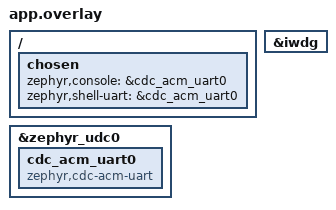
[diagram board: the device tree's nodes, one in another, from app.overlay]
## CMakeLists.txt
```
cmake_minimum_required(VERSION 3.20.0)

find_package(Zephyr REQUIRED HINTS $ENV{ZEPHYR_BASE})
project(my_zephyr_app)

target_sources(app PRIVATE src/main_latency.c)
```

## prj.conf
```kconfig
CONFIG_LOG=y
CONFIG_ZBUS_LOG_LEVEL_INF=y

CONFIG_THREAD_NAME=y

CONFIG_USB_DEVICE_STACK=y
CONFIG_USB_DEVICE_INITIALIZE_AT_BOOT=y
CONFIG_SERIAL=y
CONFIG_CONSOLE=y

CONFIG_UART_CONSOLE=y
CONFIG_UART_LINE_CTRL=y
CONFIG_ZBUS=y
CONFIG_WATCHDOG=y
CONFIG_TASK_WDT=y
CONFIG_TASK_WDT_CHANNELS=3
CONFIG_LOG_RATELIMIT=y
CONFIG_LOG_RATELIMIT_INTERVAL_MS=1000

CONFIG_SHELL=y
CONFIG_KERNEL_SHELL=y

CONFIG_THREAD_MONITOR=y
CONFIG_THREAD_NAME=y
CONFIG_INIT_STACKS=y
CONFIG_THREAD_STACK_INFO=y
# Enable DTR check so shell waits for terminal to connect
CONFIG_SHELL_BACKEND_SERIAL_CHECK_DTR=y
CONFIG_TRACING=y
CONFIG_TRACING_CTF=y
CONFIG_TRACING_ASYNC=y
CONFIG_TRACING_BACKEND_RAM=y
CONFIG_RAM_TRACING_BUFFER_SIZE=65536
CONFIG_TRACING_ISR=n
CONFIG_TRACING_SYSCALL=n

CONFIG_USE_SEGGER_RTT=y
CONFIG_SHELL_BACKEND_RTT=y
CONFIG_SEGGER_RTT_BUFFER_SIZE_UP=4096
CONFIG_SEGGER_RTT_BUFFER_SIZE_DOWN=64
```

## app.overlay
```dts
/{
	chosen {
	zephyr,console = &cdc_acm_uart0;
        zephyr,shell-uart =&cdc_acm_uart0;
	};
};

&zephyr_udc0{
	status="okay";
	cdc_acm_uart0: cdc_acm_uart0{
	compatible ="zephyr,cdc-acm-uart";
	};
};
&iwdg {
    status = "okay";
};
```

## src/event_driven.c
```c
/*
 * Zephyr Course: Intermediate - L4-TASK1: zbus listener and subscriber
 *
 * Architecture:
 * - Channel: sensor_chan carrying struct sensor_msg
 * - Publisher: sensor_thread publishes simulated sensor samples every 100 ms
 * - Listener: display_lis performs immediate display update in the publisher's context
 * - Subscriber: logger_sub thread uses zbus_sub_wait + zbus_chan_read for slower logging
 * - Observers: Both display_lis and logger_sub are registered via ZBUS_OBSERVERS on sensor_chan
 */

#include <zephyr/kernel.h>
#include <zephyr/logging/log.h>
#include <zephyr/zbus/zbus.h>

LOG_MODULE_REGISTER(l4_task1, LOG_LEVEL_INF);

#define STACK_SIZE         2048
#define SENSOR_PERIOD_MS    100
#define SENSOR_SAMPLE_COUNT  20
#define PUBLISHER_PRIORITY    5
#define SUBSCRIBER_PRIORITY   6

/* Sensor message structure */
struct sensor_msg {
    uint32_t timestamp_ms;
    int32_t temperature_mc;
    uint8_t seq;
};

/* Forward declaration for listener callback */
static void display_listener_cb(const struct zbus_channel *chan);

/* Fast display listener: executes synchronously in publisher's context */
ZBUS_LISTENER_DEFINE(display_lis, display_listener_cb);

/* Slower logging subscriber: uses message queue to unblock subscriber thread */
ZBUS_SUBSCRIBER_DEFINE(logger_sub, 8);

/*
 * ZBUS Channel Definition:
 * Carries struct sensor_msg with both display_lis and logger_sub observers
 */
ZBUS_CHAN_DEFINE(sensor_chan,
                 struct sensor_msg,
                 NULL,
                 NULL,
                 ZBUS_OBSERVERS(display_lis, logger_sub),
                 ZBUS_MSG_INIT(.timestamp_ms = 0,
                               .temperature_mc = 0,
                               .seq = 0));

/* Listener callback: runs in publisher thread context for fast notification */
static void display_listener_cb(const struct zbus_channel *chan)
{
    const struct sensor_msg *msg = zbus_chan_const_msg(chan);

    LOG_INF("[DISPLAY-LIS] (in %s context) seq=%u temp=%d mC",
            k_thread_name_get(k_current_get()),
            msg->seq,
            msg->temperature_mc);
}

/* Publisher thread: publishes sensor readings every 100 ms */
static void publisher_thread_fn(void *p1, void *p2, void *p3)
{
    ARG_UNUSED(p1); ARG_UNUSED(p2); ARG_UNUSED(p3);

    k_thread_name_set(k_current_get(), "publisher");

    LOG_INF("[PUBLISHER] Thread started, publishing %d samples every %d ms",
            SENSOR_SAMPLE_COUNT, SENSOR_PERIOD_MS);

    for (uint8_t i = 0; i < SENSOR_SAMPLE_COUNT; i++) {
        struct sensor_msg sample = {
            .timestamp_ms = k_uptime_get_32(),
            .temperature_mc = 22000 + (i * 450), /* Simulated temp: 22.0°C to 30.55°C */
            .seq = i,
        };

        LOG_INF("[PUBLISHER] Publishing sample seq=%u temp=%d mC",
                sample.seq, sample.temperature_mc);

        int ret = zbus_chan_pub(&sensor_chan, &sample, K_MSEC(100));
        if (ret != 0) {
            LOG_WRN("[PUBLISHER] zbus_chan_pub failed: %d", ret);
        }

        k_msleep(SENSOR_PERIOD_MS);
    }

    LOG_INF("[PUBLISHER] All samples published, publisher done");
}

/* Subscriber thread: performs slower decoupled logging */
static void subscriber_thread_fn(void *p1, void *p2, void *p3)
{
    ARG_UNUSED(p1); ARG_UNUSED(p2); ARG_UNUSED(p3);

    k_thread_name_set(k_current_get(), "logger");

    LOG_INF("[LOGGER-SUB] Thread started, waiting for channel events");

    const struct zbus_channel *chan = NULL;

    while (true) {
        /* Wait for notification on logger_sub */
        int ret = zbus_sub_wait(&logger_sub, &chan, K_MSEC(2000));
        if (ret != 0) {
            LOG_INF("[LOGGER-SUB] Timeout waiting for samples, subscriber completed");
            break;
        }

        /* Read the message from the channel */
        struct sensor_msg msg;
        ret = zbus_chan_read(chan, &msg, K_MSEC(100));
        if (ret != 0) {
            LOG_WRN("[LOGGER-SUB] zbus_chan_read failed: %d", ret);
            continue;
        }

        uint32_t latency_ms = k_uptime_get_32() - msg.timestamp_ms;
        LOG_INF("[LOGGER-SUB] (in %s context) seq=%u temp=%d mC latency=%u ms",
                k_thread_name_get(k_current_get()),
                msg.seq,
                msg.temperature_mc,
                latency_ms);

        /* Simulate slower logging I/O (e.g. disk or serial flash write) */
        k_msleep(180);
    }

    LOG_INF("[LOGGER-SUB] Logging thread exited cleanly");
}

/* Thread definitions */
K_THREAD_DEFINE(pub_tid, STACK_SIZE, publisher_thread_fn,
                NULL, NULL, NULL, PUBLISHER_PRIORITY, 0, 0);

K_THREAD_DEFINE(sub_tid, STACK_SIZE, subscriber_thread_fn,
                NULL, NULL, NULL, SUBSCRIBER_PRIORITY, 0, 0);

int main(void)
{
    LOG_INF("=================================================");
    LOG_INF("=== L4-TASK1: zbus Listener and Subscriber ===");
    LOG_INF("Publisher: publishes simulated sensor every %d ms", SENSOR_PERIOD_MS);
    LOG_INF("Listener: fast simulated display in publisher context");
    LOG_INF("Subscriber: slow decoupled logging via zbus_sub_wait");
    LOG_INF("=================================================");

    return 0;
}
```

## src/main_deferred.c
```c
#include<zephyr/kernel.h>
#include<zephyr/logging/log.h>

LOG_MODULE_REGISTER(task3_work1,LOG_LEVEL_INF);
#define STACK_SIZE 1024U
#define SENSOR_MS 100U

static void sensor_work_handler(struct k_work *work){
    LOG_INF("WORK HANDLER EXCUTED,EVENT HAPPEND");
}
K_WORK_DEFINE(sensor_work,sensor_work_handler);
static void sensor_sim_fn(void *p1,void *p2,void *p3){
    while(1){
        LOG_INF("SENSOR FIRED :SUMMBITING THE WORK TO THE SYSTEM WORKQUEUE");
        k_work_submit(&sensor_work);
        /*
        k_work_reschedule(&sensor_debounce_work, K_MSEC(20));
        */
        k_msleep(SENSOR_MS);
    }
}
K_THREAD_DEFINE(sensor_thread, STACK_SIZE, sensor_sim_fn, NULL, NULL, NULL, 5, 0, 0);

int main(void) {
    LOG_INF("=== L3 Homework: Workqueue Solution ===");
    return 0;
}
```

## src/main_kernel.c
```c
#include<zephyr.h>
#include <zephyr/kernel.h>
#include <zephyr/logging/log.h>

LOG_MODULE_REGISTER(demo_kernel, LOG_LEVEL_INF);

#define STACK_SIZE 1024

#define PRIO_A 7
#define PRIO_B 5
#define PRIO_C 3
#define PRIO_D -1
void t_low_fn(void *p1, void *p2, void *p3)
{
    while (1) {
        LOG_INF("T_LOW RUNNING");
        k_msleep(300);
    }
}

void t_med_fn(void *p1, void *p2, void *p3)
{
    while (1) {
        LOG_INF("T_MED_RUNNING");
        k_msleep(200);
    }
}
void t_high_fn(void *p1, void *p2, void *p3)
{
    while (1) {
        LOG_INF("T_HIGH_RUNNING");
        k_msleep(100);
    }
}

void t_cooperative_fn(void *p1,void *p2,void *p3){
    while(1){
        int count=0;
        while(count<=5){
            LOG_INF("T_COOPERATIVE_RUNNING");
            count++;
        }
     LOG_INF("TASK COMPLETED BY THE COOPERATIVE THREAD");
     k_yield();

    }
}
/***
 *  when k_yield() is called, the scheduler looks for another "Ready" thread of equal or higher priority to hand the CPU to.
 *  Since -1 is the highest priority in your system, it instantly hands the CPU right back to
 *  the cooperative thread, locking up the system
 */
K_THREAD_DEFINE(thread_a, STACK_SIZE, t_low_fn,
                NULL, NULL, NULL, PRIO_A, 0, 0);
K_THREAD_DEFINE(thread_b, STACK_SIZE, t_med_fn,
                NULL, NULL, NULL, PRIO_B, 0, 0);
K_THREAD_DEFINE(thread_c,STACK_SIZE,t_high_fn,
                NULL,NULL,NULL,PRIO_C,0,0);
K_THREAD_DEFINE(thread_d,STACK_SIZE,t_cooperative_fn,
                NULL,NULL,NULL,PRIO_D,0,0);

int main(void){  
    LOG_INF("MAIN BOOT:RTOS SCHEDULER HAS STARTED !");

    return 0;
}
```

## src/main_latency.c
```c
/*
 * Zephyr Course: Intermediate - L6-TASK1: Latency Investigation and Tracing
 *
 * 10 ms Start-Latency Guarantee:
 * - Start Latency: Elapsed time from when an event is queued by event_timer_expiry
 *   (ready_ms) until the control thread wakes up and begins execution (start_time).
 * - Guarantee: Start latency must not exceed 10 ms (DEADLINE_MS = 10).
 * - Full Processing Time: Duration of the control algorithm itself (done_time - start_time).
 * - Events:
 *     * "event_ready"  : emitted on timer expiry when control_event is posted.
 *     * "control_start": start event, emitted when control thread begins execution.
 *     * "control_done" : end event, emitted when control processing completes.
 *
 * Scheduling Root Cause & Fix:
 * - Original (Failing): CONTROL_PRIORITY = 7, MAINTENANCE_PRIORITY = 4.
 *   Since 4 < 7 in Zephyr, maintenance preempts/runs ahead of control when both become
 *   ready on timer expiry. Maintenance runs k_busy_wait(45000), causing control to start
 *   ~45 ms late and consistently violate the 10 ms guarantee.
 * - Corrected (Fixed): CONTROL_PRIORITY = 3, MAINTENANCE_PRIORITY = 7.
 *   Control runs immediately (start latency 0-1 ms <= 10 ms), and maintenance executes
 *   during subsequent idle time. 0 deadline misses.
 */

#include <zephyr/kernel.h>
#include <zephyr/logging/log.h>
#include <zephyr/tracing/tracing.h>

LOG_MODULE_REGISTER(homework, LOG_LEVEL_INF);

#define STACK_SIZE            2048
#define EVENT_PERIOD_MS        250
#define MAINTENANCE_LOAD_US  45000
#define DEADLINE_MS             10

/* Set to 1 for the corrected priority assignment, 0 for original failing workload */
#ifndef FIX_SCHEDULING_PRIORITY
#define FIX_SCHEDULING_PRIORITY 1
#endif

#if FIX_SCHEDULING_PRIORITY
#define CONTROL_PRIORITY         3
#define MAINTENANCE_PRIORITY     7
#else
#define CONTROL_PRIORITY         7
#define MAINTENANCE_PRIORITY     4
#endif

struct control_event {
    uint32_t seq;
    uint32_t ready_ms;
};

K_MSGQ_DEFINE(control_queue, sizeof(struct control_event), 4, 4);
K_SEM_DEFINE(maintenance_start, 0, 1);

/* ================================================================== */
/*  Timer expiry: creates one control event                           */
/* ================================================================== */

static void event_timer_expiry(struct k_timer *timer)
{
    ARG_UNUSED(timer);

    static uint32_t seq;
    struct control_event event = {
        .seq = seq++,
        .ready_ms = k_uptime_get_32(),
    };

    /* Timer expiry runs in interrupt context, so never wait here. */
    int ret = k_msgq_put(&control_queue, &event, K_NO_WAIT);

    if (ret != 0) {
        return;
    }

    /* Both threads become ready when the timer interrupt returns. */
    k_sem_give(&maintenance_start);

    /* Application trace event for event availability */
    sys_trace_named_event("event_ready", event.seq, k_msgq_num_used_get(&control_queue));
}

K_TIMER_DEFINE(event_timer, event_timer_expiry, NULL);

/* ================================================================== */
/*  Control thread                                                   */
/* ================================================================== */

static void control_fn(void *p1, void *p2, void *p3)
{
    ARG_UNUSED(p1); ARG_UNUSED(p2); ARG_UNUSED(p3);

    k_thread_name_set(k_current_get(), "control");

    uint32_t deadline_misses = 0;
    uint32_t total_events = 0;

    while (true) {
        struct control_event event;
        int ret = k_msgq_get(&control_queue, &event, K_FOREVER);

        if (ret != 0) {
            LOG_ERR("[CONTROL] receive failed: %d", ret);
            continue;
        }

        /* Start event: records the instant control execution begins */
        uint32_t start_time = k_uptime_get_32();
        uint32_t start_latency = start_time - event.ready_ms;
        total_events++;

        sys_trace_named_event("control_start", event.seq, start_latency);

        /* Evaluate 10 ms start-latency guarantee */
        if (start_latency > DEADLINE_MS) {
            deadline_misses++;
            LOG_WRN_RATELIMIT("[CONTROL] DEADLINE MISS: seq=%u start_latency=%u ms (> %u ms guarantee) total_misses=%u",
                              event.seq, start_latency, DEADLINE_MS, deadline_misses);
        } else {
            LOG_INF("[CONTROL] OK: seq=%u start_latency=%u ms (<= %u ms guarantee) total=%u",
                    event.seq, start_latency, DEADLINE_MS, total_events);
        }

        /* Full processing workload: simulated control processing */
        k_busy_wait(1000);

        uint32_t done_time = k_uptime_get_32();
        uint32_t processing_time = done_time - start_time;

        /* End event: records completion of control processing */
        sys_trace_named_event("control_done", event.seq, processing_time);

        LOG_INF("[CONTROL] processed seq=%u", event.seq);
    }
}

/* ================================================================== */
/*  Background maintenance thread                                    */
/* ================================================================== */

static void maintenance_fn(void *p1, void *p2, void *p3)
{
    ARG_UNUSED(p1); ARG_UNUSED(p2); ARG_UNUSED(p3);

    k_thread_name_set(k_current_get(), "maintenance");

    while (true) {
        k_sem_take(&maintenance_start, K_FOREVER);

        /* This work is important, but it has no short deadline. */
        k_busy_wait(MAINTENANCE_LOAD_US);
    }
}

K_THREAD_DEFINE(control, STACK_SIZE, control_fn,
                NULL, NULL, NULL, CONTROL_PRIORITY, 0, 0);

K_THREAD_DEFINE(maintenance, STACK_SIZE, maintenance_fn,
                NULL, NULL, NULL, MAINTENANCE_PRIORITY, 0, 0);

int main(void)
{
    LOG_INF("=== L6 Homework: Runtime Investigation ===");
    LOG_INF("Control work must start within 10 ms");
    LOG_INF("Inspect, measure, trace, explain, and correct the delay");

    k_timer_start(&event_timer, K_MSEC(500), K_MSEC(EVENT_PERIOD_MS));

    return 0;
}
```

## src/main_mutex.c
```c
/*
 * Zephyr Course: Intermediate - L2-TASK1: Protecting shared state with a mutex
 *
 * EXPLANATION OF CONCURRENT READ-MODIFY-WRITE AND LOST UPDATES:
 * -------------------------------------------------------------
 * When multiple threads access a shared variable without synchronization, a classic
 * read-modify-write race condition occurs.
 *
 * In the UNPROTECTED variant:
 * 1. Thread A reads bank_balance (e.g. 100) into its local stack variable local_copy.
 * 2. Before Thread A can write back the updated value (100 + 50 = 150), a context switch
 *    or voluntary delay (k_msleep) occurs.
 * 3. Thread B runs and also reads bank_balance. Since Thread A has not committed its write,
 *    Thread B still sees 100.
 * 4. Thread A resumes and writes 150 to bank_balance.
 * 5. Thread B resumes and writes 120 (100 + 20) to bank_balance, completely overwriting
 *    Thread A's deposit of $50! Thread A's update is permanently lost.
 *
 * Over 10 iterations per thread (10 deposits of $50 and 10 deposits of $20):
 * - Initial balance:  $100
 * - Expected total:   $100 + (10 * $50) + (10 * $20) = $800
 * - Unprotected total: Significantly lower than $800 because concurrent interleaving
 *                      repeatedly overwrites pending deposits.
 *
 * In the PROTECTED variant (with bank_mutex):
 * 1. Thread A acquires bank_mutex via k_mutex_lock(&bank_mutex, K_FOREVER).
 * 2. Thread A reads bank_balance, performs calculations, and even during delays (k_msleep),
 *    the mutex remains locked.
 * 3. Thread B attempts to lock bank_mutex, but is placed into the PENDING state by the scheduler.
 * 4. Thread A writes back the updated balance (150) and unlocks bank_mutex.
 * 5. Thread B unblocks, locks bank_mutex, and reads the fresh, already-updated balance (150).
 * 6. Thread B updates and writes back 170.
 * - Protected total: Exactly $800. No updates are lost, and atomic serializability is guaranteed.
 */

#include <zephyr/kernel.h>
#include <zephyr/logging/log.h>

LOG_MODULE_REGISTER(race_demo, LOG_LEVEL_INF);

#define STACK_SIZE         1024
#define PRIORITY           7
#define NUM_DEPOSITS       10
#define INITIAL_BALANCE    100
#define DEPOSIT_A          50
#define DEPOSIT_B          20
#define EXPECTED_TOTAL     (INITIAL_BALANCE + (NUM_DEPOSITS * DEPOSIT_A) + (NUM_DEPOSITS * DEPOSIT_B))

/* Shared bank balance */
static volatile int bank_balance = INITIAL_BALANCE;

/* Mutex protecting bank_balance during protected run */
K_MUTEX_DEFINE(bank_mutex);

/* Semaphores to coordinate runs between main and worker threads */
static K_SEM_DEFINE(sem_unprotected_start, 0, 2);
static K_SEM_DEFINE(sem_unprotected_done_a, 0, 1);
static K_SEM_DEFINE(sem_unprotected_done_b, 0, 1);

static K_SEM_DEFINE(sem_protected_start, 0, 2);
static K_SEM_DEFINE(sem_protected_done_a, 0, 1);
static K_SEM_DEFINE(sem_protected_done_b, 0, 1);

/* =====================================================================
 * UNPROTECTED WORKER THREADS (Demonstrating Race Condition & Lost Updates)
 * ===================================================================== */

void unprotected_thread_a(void *p1, void *p2, void *p3)
{
    ARG_UNUSED(p1); ARG_UNUSED(p2); ARG_UNUSED(p3);

    k_sem_take(&sem_unprotected_start, K_FOREVER);
    LOG_INF("[UNPROTECTED A] Started 10 deposits of $%d", DEPOSIT_A);

    for (int i = 0; i < NUM_DEPOSITS; i++) {
        /* 1. Read shared balance into local copy */
        int local_copy = bank_balance;
        LOG_DBG("[UNPROTECTED A] Read balance: %d (iter %d)", local_copy, i + 1);

        /* 2. Artificial delay between read and write gives Thread B window to read stale state */
        k_msleep(40);

        /* 3. Modify and write back */
        local_copy += DEPOSIT_A;
        bank_balance = local_copy;
        LOG_INF("[UNPROTECTED A] Wrote balance: %d (Deposit +$%d, iter %d)",
                bank_balance, DEPOSIT_A, i + 1);

        k_msleep(20);
    }

    LOG_INF("[UNPROTECTED A] Finished all deposits");
    k_sem_give(&sem_unprotected_done_a);
}

void unprotected_thread_b(void *p1, void *p2, void *p3)
{
    ARG_UNUSED(p1); ARG_UNUSED(p2); ARG_UNUSED(p3);

    k_sem_take(&sem_unprotected_start, K_FOREVER);
    LOG_WRN("[UNPROTECTED B] Started 10 deposits of $%d", DEPOSIT_B);

    for (int i = 0; i < NUM_DEPOSITS; i++) {
        /* Small phase offset ensures Thread B reads while Thread A is delaying before write */
        k_msleep(15);

        /* 1. Read shared balance into local copy (reads STALE balance!) */
        int local_copy = bank_balance;
        LOG_DBG("[UNPROTECTED B] Read balance: %d (iter %d)", local_copy, i + 1);

        /* 2. Delay before write */
        k_msleep(40);

        /* 3. Modify and write back (OVERWRITES Thread A's update!) */
        local_copy += DEPOSIT_B;
        bank_balance = local_copy;
        LOG_WRN("[UNPROTECTED B] Wrote balance: %d (Deposit +$%d, iter %d)",
                bank_balance, DEPOSIT_B, i + 1);

        k_msleep(20);
    }

    LOG_WRN("[UNPROTECTED B] Finished all deposits");
    k_sem_give(&sem_unprotected_done_b);
}

/* =====================================================================
 * PROTECTED WORKER THREADS (Demonstrating Mutex Mutual Exclusion)
 * ===================================================================== */

void protected_thread_a(void *p1, void *p2, void *p3)
{
    ARG_UNUSED(p1); ARG_UNUSED(p2); ARG_UNUSED(p3);

    k_sem_take(&sem_protected_start, K_FOREVER);
    LOG_INF("[PROTECTED A] Started 10 deposits of $%d", DEPOSIT_A);

    for (int i = 0; i < NUM_DEPOSITS; i++) {
        /* Acquire mutex before critical section */
        k_mutex_lock(&bank_mutex, K_FOREVER);

        int local_copy = bank_balance;
        /* Delay inside critical section - mutex holds off Thread B */
        k_msleep(40);
        local_copy += DEPOSIT_A;
        bank_balance = local_copy;

        LOG_INF("[PROTECTED A] Deposited +$%d -> Balance: %d (iter %d)",
                DEPOSIT_A, bank_balance, i + 1);

        /* Release mutex after write */
        k_mutex_unlock(&bank_mutex);

        k_msleep(20);
    }

    LOG_INF("[PROTECTED A] Finished all deposits");
    k_sem_give(&sem_protected_done_a);
}

void protected_thread_b(void *p1, void *p2, void *p3)
{
    ARG_UNUSED(p1); ARG_UNUSED(p2); ARG_UNUSED(p3);

    k_sem_take(&sem_protected_start, K_FOREVER);
    LOG_WRN("[PROTECTED B] Started 10 deposits of $%d", DEPOSIT_B);

    for (int i = 0; i < NUM_DEPOSITS; i++) {
        k_msleep(15);

        /* Thread B waits for bank_mutex if Thread A is in its critical section */
        k_mutex_lock(&bank_mutex, K_FOREVER);

        int local_copy = bank_balance;
        k_msleep(40);
        local_copy += DEPOSIT_B;
        bank_balance = local_copy;

        LOG_WRN("[PROTECTED B] Deposited +$%d -> Balance: %d (iter %d)",
                DEPOSIT_B, bank_balance, i + 1);

        k_mutex_unlock(&bank_mutex);

        k_msleep(20);
    }

    LOG_WRN("[PROTECTED B] Finished all deposits");
    k_sem_give(&sem_protected_done_b);
}

/* Thread definitions */
K_THREAD_DEFINE(unprot_a, STACK_SIZE, unprotected_thread_a, NULL, NULL, NULL, PRIORITY, 0, 0);
K_THREAD_DEFINE(unprot_b, STACK_SIZE, unprotected_thread_b, NULL, NULL, NULL, PRIORITY, 0, 0);
K_THREAD_DEFINE(prot_a,   STACK_SIZE, protected_thread_a,   NULL, NULL, NULL, PRIORITY, 0, 0);
K_THREAD_DEFINE(prot_b,   STACK_SIZE, protected_thread_b,   NULL, NULL, NULL, PRIORITY, 0, 0);

int main(void)
{
    LOG_INF("=================================================================");
    LOG_INF("=== L2-TASK1: Protecting Shared State With a Mutex ===");
    LOG_INF("Initial Bank Balance:      $%d", INITIAL_BALANCE);
    LOG_INF("Thread A: 10 deposits of   $%d", DEPOSIT_A);
    LOG_INF("Thread B: 10 deposits of   $%d", DEPOSIT_B);
    LOG_INF("Expected Final Total:      $%d", EXPECTED_TOTAL);
    LOG_INF("=================================================================");

    /* -------------------------------------------------------------
     * PHASE 1: UNPROTECTED RUN (No Mutex)
     * ------------------------------------------------------------- */
    LOG_INF("--- Starting Phase 1: Unprotected Run (no mutex) ---");
    bank_balance = INITIAL_BALANCE;

    /* Release unprotected workers */
    k_sem_give(&sem_unprotected_start);
    k_sem_give(&sem_unprotected_start);

    /* Wait for both workers to finish all deposits */
    k_sem_take(&sem_unprotected_done_a, K_FOREVER);
    k_sem_take(&sem_unprotected_done_b, K_FOREVER);

    int unprotected_final = bank_balance;
    int lost_amount = EXPECTED_TOTAL - unprotected_final;

    LOG_ERR("Phase 1 Result (Unprotected):");
    LOG_ERR("  Expected Balance: $%d", EXPECTED_TOTAL);
    LOG_ERR("  Actual Balance:   $%d", unprotected_final);
    LOG_ERR("  Lost Updates:     $%d (lost due to concurrent read-modify-write race!)", lost_amount);

    k_msleep(500);

    /* -------------------------------------------------------------
     * PHASE 2: PROTECTED RUN (With bank_mutex)
     * ------------------------------------------------------------- */
    LOG_INF("--- Starting Phase 2: Protected Run (with bank_mutex) ---");
    bank_balance = INITIAL_BALANCE;

    /* Release protected workers */
    k_sem_give(&sem_protected_start);
    k_sem_give(&sem_protected_start);

    /* Wait for both protected workers to finish all deposits */
    k_sem_take(&sem_protected_done_a, K_FOREVER);
    k_sem_take(&sem_protected_done_b, K_FOREVER);

    int protected_final = bank_balance;

    LOG_INF("Phase 2 Result (Protected with bank_mutex):");
    LOG_INF("  Expected Balance: $%d", EXPECTED_TOTAL);
    LOG_INF("  Actual Balance:   $%d", protected_final);
    LOG_INF("  Lost Updates:     $0 (all deposits successfully committed)");

    /* -------------------------------------------------------------
     * COMPARISON SUMMARY
     * ------------------------------------------------------------- */
    LOG_INF("=================================================================");
    LOG_INF("=== FINAL COMPARISON AFTER ALL DEPOSITS ARE DONE ===");
    LOG_INF("Initial balance:            $%d", INITIAL_BALANCE);
    LOG_INF("Total deposits attempted:   $%d (10 x $50 + 10 x $20)",
            (NUM_DEPOSITS * DEPOSIT_A) + (NUM_DEPOSITS * DEPOSIT_B));
    LOG_INF("Expected final balance:     $%d", EXPECTED_TOTAL);
    LOG_INF("Unprotected final balance:  $%d (LOST $%d updates)",
            unprotected_final, lost_amount);
    LOG_INF("Protected final balance:    $%d (MUTEX PRESERVED EXACT TOTAL)",
            protected_final);
    LOG_INF("Difference preserved:       $%d saved from race condition corruption",
            protected_final - unprotected_final);
    LOG_INF("=================================================================");

    return 0;
}
```

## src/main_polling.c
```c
#include <zephyr/logging/log.h>
#include <stdbool.h>

LOG_MODULE_REGISTER(task3,LOG_LEVEL_INF);
K_SEM_DEFINE(my_sem,1,1);

#define STACK_SIZE 1024U
#define SENSOR_MS 100U
#define POLL_MS 10U
#define EVENT_COUNT 10U

static volatile bool sensor_flag = false;
static int wasted_wakeups = 0;

static void sensor_sim_fn(void *p1, void *p2,void *p3){
    while(1){
        k_sem_take(&my_sem,K_FOREVER);
        sensor_flag=true;
        k_sem_give(&my_sem);
        LOG_INF("THE FLAG IS SET AND SEM IS GIVEN");
        k_msleep(SENSOR_MS);
    }
}

static void polling_fn(void *p1, void *p2, void *p3) {
    bool current_flag;

    while(1) {
        /* Take semaphore to safely read and clear the flag */
        k_sem_take(&my_sem, K_FOREVER);
        
        current_flag = sensor_flag;
        if (current_flag == true) {
            sensor_flag = false;
        }
        
        /* ALWAYS give the semaphore back */
        k_sem_give(&my_sem);

        /* Process outside the lock to minimize blocking */
        if (current_flag) {
            LOG_INF("POLLING: Event processed. (Wasted wakeups since last event: %d)", wasted_wakeups);
            wasted_wakeups = 0;
        } else {
            wasted_wakeups++;
        }
        
        k_msleep(POLL_MS);
    }
}

K_THREAD_DEFINE(sensor_thread,  STACK_SIZE, sensor_sim_fn, NULL, NULL, NULL, 5, 0, 0);
K_THREAD_DEFINE(polling_thread, STACK_SIZE, polling_fn,    NULL, NULL, NULL, 5, 0, 0);int main(void)
{
    LOG_INF("=== L3 Homework: Polling to Workqueue ===");
    LOG_INF("Starter: polling every %dms, sensor fires every %dms",
            POLL_MS, SENSOR_MS);
    LOG_INF("Expected wasted wakeups: ~%d per event",
            (SENSOR_MS / POLL_MS) - 1);
    LOG_INF("Run this, count wakeups, then convert to workqueue.");

    /* Wait long enough for all events to complete */
    

    return 0;
}
```

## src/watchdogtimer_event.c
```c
#include <zephyr/kernel.h>
#include <zephyr/task_wdt/task_wdt.h>
#include <zephyr/drivers/watchdog.h>
#include <zephyr/logging/log.h>
#include <zephyr/zbus/zbus.h>
#include <zephyr/tracing/tracing.h>




LOG_MODULE_REGISTER(pipeline_test, LOG_LEVEL_INF); /* Added semicolon */

#define QUEUE_SIZE 8
#define WDT_TIMEOUT_MS 2000
#define DEADLINE_MS 50

struct pipeline_data {
    int value;
    uint32_t timestamps_ms;
};
K_MSGQ_DEFINE(consumer_queue, sizeof(struct pipeline_data), QUEUE_SIZE, 4);

void zbus_listener_callback(const struct zbus_channel *chan) {
    /* Bug 1 Fix: use zbus_chan_const_msg() directly — avoids corrupting the
     * pointer by passing &received_data (address of a pointer) into
     * zbus_chan_read(), which overwrote it with raw bytes causing
     * garbage latency (281162 ms) and corrupted SEQ numbers. */
    const struct pipeline_data *msg = zbus_chan_const_msg(chan);
    if (k_msgq_put(&consumer_queue, msg, K_NO_WAIT) != 0) {
        LOG_WRN("Consumer Inbox FULL! Dropping data: %d", msg->value);
    }
}
ZBUS_LISTENER_DEFINE(pipeline_listener, zbus_listener_callback);

ZBUS_CHAN_DEFINE(sensor_data_chan,
                 struct pipeline_data,
                 NULL,
                 NULL,
                 ZBUS_OBSERVERS(pipeline_listener), /* Fixed: Added 'S' */
                 ZBUS_MSG_INIT(0)
);

void wdt_callback(int channel_id, void *user_data) {
    LOG_ERR("FATAL: WATCHDOG TIMER EXPIRED, CHANNEL ID %d is unresponsive", channel_id);
    LOG_ERR("SYSTEM WILL NOW HARDWARE REBOOT");
}

void producer_thread(void) {
    struct pipeline_data data = { .value = 0,.timestamps_ms=0 };
    while(1) {
        data.timestamps_ms=k_uptime_get_32();
        zbus_chan_pub(&sensor_data_chan, &data, K_NO_WAIT);
        LOG_INF("event_ready seq= %d ,queue =%u", data.value,k_msgq_num_used_get(&consumer_queue));
        sys_trace_named_event("event_ready",data.value,k_msgq_num_used_get(&consumer_queue));
        data.value++;
        k_msleep(200);
    }
}

void consumer_thread(void) {
    struct pipeline_data data_in={0}; /* Fixed: struct typo */
    int process_count = 0;
    static uint32_t deadline_miss=0;

    int wdt_channel = task_wdt_add(WDT_TIMEOUT_MS, wdt_callback, NULL);
    if(wdt_channel < 0) {
        LOG_ERR("FAILED TO ADD TASK WDT CHANNEL");
        return;
    }
    
  while (1) {
        if (k_msgq_get(&consumer_queue, &data_in, K_MSEC(100)) == 0) {
            uint32_t latency_ms = k_uptime_get_32() - data_in.timestamps_ms;

            if (latency_ms > DEADLINE_MS) {
                deadline_miss++;
                LOG_WRN_RATELIMIT("deadline_miss count=%u, SEQ=%d, latency_ms=%u",
                                  deadline_miss, data_in.value, latency_ms);
            } else {
                LOG_INF("event_done seq=%d latency_ms=%u result=OK", 
                        data_in.value, latency_ms);
                        sys_trace_named_event("event_done", data_in.value, latency_ms);
                process_count++;
            }
        }

        /* Feed the watchdog to prove this thread is not frozen */
        task_wdt_feed(wdt_channel);

        /* SIMULATE A STUCK CONSUMER */
        if (process_count == 600) {
            LOG_WRN("Simulating a catastrophic consumer freeze...");
            k_msleep(10000); 
        }
    }
}

void health_thread(void) {
    while(1) {
        uint32_t used = k_msgq_num_used_get(&consumer_queue);
        if (used >= (QUEUE_SIZE * 3 / 4)) {
            LOG_WRN("QUEUE CAPACITY IS CRITICAL %d filled", used);
        }
        k_msleep(500);
    }
}

K_THREAD_DEFINE(prod_id, 1024, (k_thread_entry_t)producer_thread, NULL, NULL, NULL, 5, 0, 0);
K_THREAD_DEFINE(cons_id, 1024, (k_thread_entry_t)consumer_thread, NULL, NULL, NULL, 5, 0, 0);
K_THREAD_DEFINE(hlth_id, 1024, (k_thread_entry_t)health_thread, NULL, NULL, NULL, 4, 0, 0);

int main(void) {
    LOG_INF("STARTING THE ZBUS pipeline & watchdog test");
    const struct device *hw_wdt = DEVICE_DT_GET(DT_NODELABEL(iwdg));
    k_thread_name_set(prod_id, "producer");
    k_thread_name_set(cons_id, "consumer");
    k_thread_name_set(hlth_id, "health");
    if(!device_is_ready(hw_wdt)) {
        LOG_WRN("HARDWARE NOT READY, RUNNING TASK WDT IN SOFTWARE ONLY MODE");
        task_wdt_init(NULL);
    } else {
        task_wdt_init(hw_wdt);
    }
    return 0;
}
```
